# ATSAM3U2E register map
Vendor: Atmel; Series: SAM3U; File version: 0
CPU: CM3 r2p0, selectable endian, MPU, no FPU, 4 interrupt priority bits
Registers are 32-bit, read-write, reset 0x0 unless marked. A register's access mark holds for its fields unless they carry their own. Offsets are from the block's base; [hi:lo] are bit positions; {n}, {i} and the like mark numbered series; 'fields as' and 'values as' point back to an identical list.

## USART0 — Universal Synchronous Asynchronous Receiver Transmitter 0
Base 0x40090000; register names take the prefix USART0_
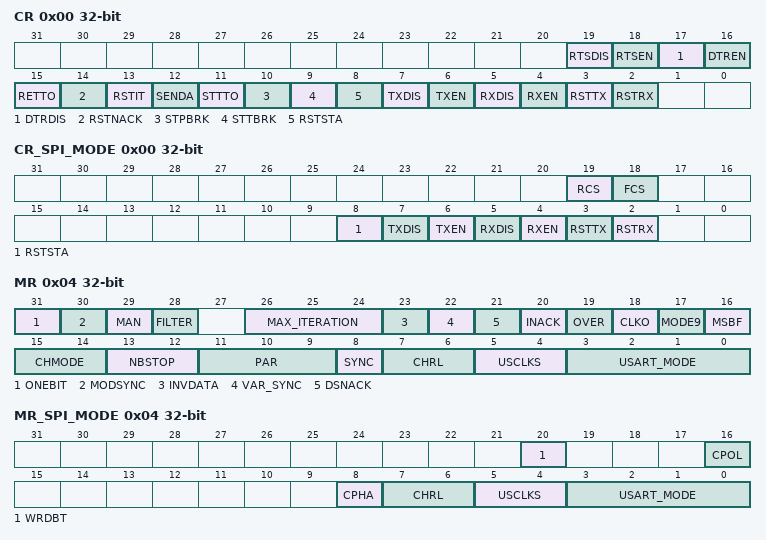
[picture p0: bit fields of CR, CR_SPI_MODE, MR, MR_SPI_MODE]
0x00 CR wo reset not defined — Control Register
  [19] RTSDIS — Request to Send Disable
  [18] RTSEN — Request to Send Enable
  [17] DTRDIS — Data Terminal Ready Disable
  [16] DTREN — Data Terminal Ready Enable
  [15] RETTO — Rearm Time-out
  [14] RSTNACK — Reset Non Acknowledge
  [13] RSTIT — Reset Iterations
  [12] SENDA — Send Address
  [11] STTTO — Start Time-out
  [10] STPBRK — Stop Break
  [9] STTBRK — Start Break
  [8] RSTSTA — Reset Status Bits
  [7] TXDIS — Transmitter Disable
  [6] TXEN — Transmitter Enable
  [5] RXDIS — Receiver Disable
  [4] RXEN — Receiver Enable
  [3] RSTTX — Reset Transmitter
  [2] RSTRX — Reset Receiver
0x00 CR_SPI_MODE wo reset not defined (SPI_MODE view) — Control Register
  [19] RCS — Release SPI Chip Select
  [18] FCS — Force SPI Chip Select
  [8] RSTSTA — Reset Status Bits
  [7] TXDIS — Transmitter Disable
  [6] TXEN — Transmitter Enable
  [5] RXDIS — Receiver Disable
  [4] RXEN — Receiver Enable
  [3] RSTTX — Reset Transmitter
  [2] RSTRX — Reset Receiver
0x04 MR reset not defined — Mode Register
  [31] ONEBIT — Start Frame Delimiter Selector
  [30] MODSYNC — Manchester Synchronization Mode
  [29] MAN — Manchester Encoder/Decoder Enable
  [28] FILTER — Infrared Receive Line Filter
  [26:24] MAX_ITERATION — Maximum Number of Automatic Iteration
  [23] INVDATA — Inverted Data
  [22] VAR_SYNC — Variable Synchronization of Command/Data Sync Start Frame Delimiter
  [21] DSNACK — Disable Successive NACK
  [20] INACK — Inhibit Non Acknowledge
  [19] OVER — Oversampling Mode
  [18] CLKO — Clock Output Select
  [17] MODE9 — 9-bit Character Length
  [16] MSBF — Bit Order
  [15:14] CHMODE — Channel Mode
    0=NORMAL (Normal Mode); 1=AUTOMATIC (Automatic Echo. Receiver input is connected to the TXD pin.); 2=LOCAL_LOOPBACK (Local Loopback. Transmitter output is connected to the Receiver Input.); 3=REMOTE_LOOPBACK (Remote Loopback. RXD pin is internally connected to the TXD pin.)
  [13:12] NBSTOP — Number of Stop Bits
    0=1_BIT (1 stop bit); 1=1_5_BIT (1.5 stop bit (SYNC = 0) or reserved (SYNC = 1)); 2=2_BIT (2 stop bits)
  [11:9] PAR — Parity Type
    0=EVEN (Even parity); 1=ODD (Odd parity); 2=SPACE (Parity forced to 0 (Space)); 3=MARK (Parity forced to 1 (Mark)); 4=NO (No parity); 6=MULTIDROP (Multidrop mode)
  [8] SYNC — Synchronous Mode Select
  [7:6] CHRL — Character Length.
    {v}={v+5}_BIT (Character length is {v+5} bits) (v=0..3)
  [5:4] USCLKS — Clock Selection
    0=MCK (Master Clock MCK is selected); 1=DIV (Internal Clock Divided MCK/DIV (DIV=8) is selected); 3=SCK (Serial Clock SLK is selected)
  [3:0] USART_MODE — USART Mode of Operation
    0=NORMAL (Normal mode); 1=RS485; 2=HW_HANDSHAKING (Hardware Handshaking); 3=MODEM; 4=IS07816_T_0 (IS07816 Protocol: T = 0); 6=IS07816_T_1 (IS07816 Protocol: T = 1); 8=IRDA; 14=SPI_MASTER; 15=SPI_SLAVE
0x04 MR_SPI_MODE reset not defined (SPI_MODE view) — Mode Register
  [20] WRDBT — Wait Read Data Before Transfer
  [16] CPOL — SPI Clock Polarity
  [8] CPHA — SPI Clock Phase
  [7:6] CHRL — Character Length.
    3=8_BIT (Character length is 8 bits)
  [5:4] USCLKS — Clock Selection
    values as MR.USCLKS
  [3:0] USART_MODE — USART Mode of Operation
    14=SPI_MASTER; 15=SPI_SLAVE
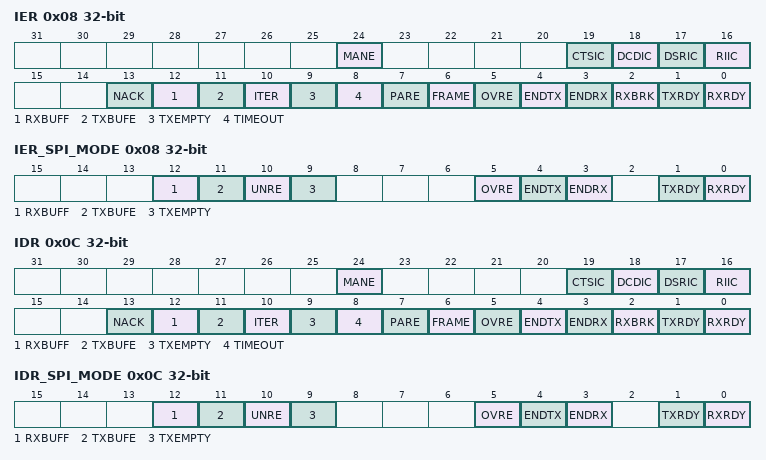
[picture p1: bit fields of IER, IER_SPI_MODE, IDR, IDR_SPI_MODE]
0x08 IER wo reset not defined — Interrupt Enable Register
  [24] MANE — Manchester Error Interrupt Enable
  [19] CTSIC — Clear to Send Input Change Interrupt Enable
  [18] DCDIC — Data Carrier Detect Input Change Interrupt Enable
  [17] DSRIC — Data Set Ready Input Change Enable
  [16] RIIC — Ring Indicator Input Change Enable
  [13] NACK — Non AcknowledgeInterrupt Enable
  [12] RXBUFF — Buffer Full Interrupt Enable (available in all USART modes of operation)
  [11] TXBUFE — Buffer Empty Interrupt Enable (available in all USART modes of operation)
  [10] ITER — Max number of Repetitions Reached Interrupt Enable
  [9] TXEMPTY — TXEMPTY Interrupt Enable
  [8] TIMEOUT — Time-out Interrupt Enable
  [7] PARE — Parity Error Interrupt Enable
  [6] FRAME — Framing Error Interrupt Enable
  [5] OVRE — Overrun Error Interrupt Enable
  [4] ENDTX — End of Transmit Interrupt Enable (available in all USART modes of operation)
  [3] ENDRX — End of Receive Transfer Interrupt Enable (available in all USART modes of operation)
  [2] RXBRK — Receiver Break Interrupt Enable
  [1] TXRDY — TXRDY Interrupt Enable
  [0] RXRDY — RXRDY Interrupt Enable
0x08 IER_SPI_MODE wo reset not defined (SPI_MODE view) — Interrupt Enable Register
  [12] RXBUFF
  [11] TXBUFE
  [10] UNRE — SPI Underrun Error Interrupt Enable
  [9] TXEMPTY — TXEMPTY Interrupt Enable
  [5] OVRE — Overrun Error Interrupt Enable
  [4] ENDTX
  [3] ENDRX
  [1] TXRDY — TXRDY Interrupt Enable
  [0] RXRDY — RXRDY Interrupt Enable
0x0C IDR wo reset not defined — Interrupt Disable Register
  [24] MANE — Manchester Error Interrupt Disable
  [19] CTSIC — Clear to Send Input Change Interrupt Disable
  [18] DCDIC — Data Carrier Detect Input Change Interrupt Disable
  [17] DSRIC — Data Set Ready Input Change Disable
  [16] RIIC — Ring Indicator Input Change Disable
  [13] NACK — Non AcknowledgeInterrupt Disable
  [12] RXBUFF — Buffer Full Interrupt Disable (available in all USART modes of operation)
  [11] TXBUFE — Buffer Empty Interrupt Disable (available in all USART modes of operation)
  [10] ITER — Max Number of Repetitions Reached Interrupt Disable
  [9] TXEMPTY — TXEMPTY Interrupt Disable
  [8] TIMEOUT — Time-out Interrupt Disable
  [7] PARE — Parity Error Interrupt Disable
  [6] FRAME — Framing Error Interrupt Disable
  [5] OVRE — Overrun Error Interrupt Enable
  [4] ENDTX — End of Transmit Interrupt Disable (available in all USART modes of operation)
  [3] ENDRX — End of Receive Transfer Interrupt Disable (available in all USART modes of operation)
  [2] RXBRK — Receiver Break Interrupt Disable
  [1] TXRDY — TXRDY Interrupt Disable
  [0] RXRDY — RXRDY Interrupt Disable
0x0C IDR_SPI_MODE wo reset not defined (SPI_MODE view) — Interrupt Disable Register
  [12] RXBUFF
  [11] TXBUFE
  [10] UNRE — SPI Underrun Error Interrupt Disable
  [9] TXEMPTY — TXEMPTY Interrupt Disable
  [5] OVRE — Overrun Error Interrupt Disable
  [4] ENDTX
  [3] ENDRX
  [1] TXRDY — TXRDY Interrupt Disable
  [0] RXRDY — RXRDY Interrupt Disable
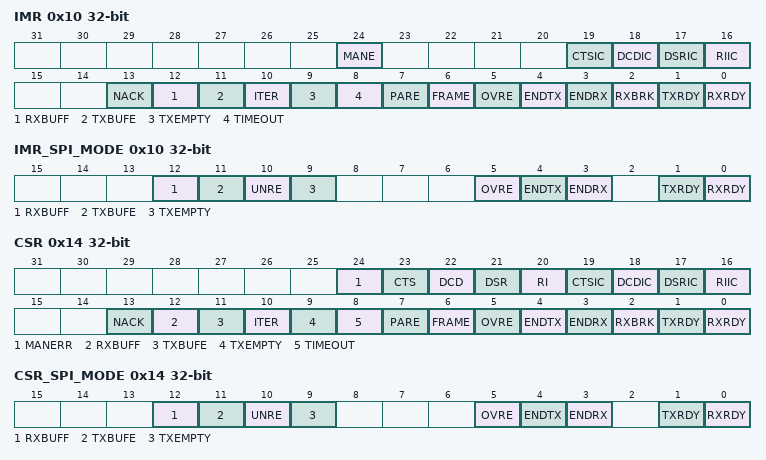
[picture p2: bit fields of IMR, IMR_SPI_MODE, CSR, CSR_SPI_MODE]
0x10 IMR ro — Interrupt Mask Register
  [24] MANE — Manchester Error Interrupt Mask
  [19] CTSIC — Clear to Send Input Change Interrupt Mask
  [18] DCDIC — Data Carrier Detect Input Change Interrupt Mask
  [17] DSRIC — Data Set Ready Input Change Mask
  [16] RIIC — Ring Indicator Input Change Mask
  [13] NACK — Non AcknowledgeInterrupt Mask
  [12] RXBUFF — Buffer Full Interrupt Mask (available in all USART modes of operation)
  [11] TXBUFE — Buffer Empty Interrupt Mask (available in all USART modes of operation)
  [10] ITER — Max Number of Repetitions Reached Interrupt Mask
  [9] TXEMPTY — TXEMPTY Interrupt Mask
  [8] TIMEOUT — Time-out Interrupt Mask
  [7] PARE — Parity Error Interrupt Mask
  [6] FRAME — Framing Error Interrupt Mask
  [5] OVRE — Overrun Error Interrupt Mask
  [4] ENDTX — End of Transmit Interrupt Mask (available in all USART modes of operation)
  [3] ENDRX — End of Receive Transfer Interrupt Mask (available in all USART modes of operation)
  [2] RXBRK — Receiver Break Interrupt Mask
  [1] TXRDY — TXRDY Interrupt Mask
  [0] RXRDY — RXRDY Interrupt Mask
0x10 IMR_SPI_MODE ro (SPI_MODE view) — Interrupt Mask Register
  [12] RXBUFF
  [11] TXBUFE
  [10] UNRE — SPI Underrun Error Interrupt Mask
  [9] TXEMPTY — TXEMPTY Interrupt Mask
  [5] OVRE — Overrun Error Interrupt Mask
  [4] ENDTX
  [3] ENDRX
  [1] TXRDY — TXRDY Interrupt Mask
  [0] RXRDY — RXRDY Interrupt Mask
0x14 CSR ro reset not defined — Channel Status Register
  [24] MANERR — Manchester Error
  [23] CTS — Image of CTS Input
  [22] DCD — Image of DCD Input
  [21] DSR — Image of DSR Input
  [20] RI — Image of RI Input
  [19] CTSIC — Clear to Send Input Change Flag
  [18] DCDIC — Data Carrier Detect Input Change Flag
  [17] DSRIC — Data Set Ready Input Change Flag
  [16] RIIC — Ring Indicator Input Change Flag
  [13] NACK — Non AcknowledgeInterrupt
  [12] RXBUFF — Reception Buffer Full
  [11] TXBUFE — Transmission Buffer Empty
  [10] ITER — Max Number of Repetitions Reached
  [9] TXEMPTY — Transmitter Empty
  [8] TIMEOUT — Receiver Time-out
  [7] PARE — Parity Error
  [6] FRAME — Framing Error
  [5] OVRE — Overrun Error
  [4] ENDTX — End of Transmitter Transfer
  [3] ENDRX — End of Receiver Transfer
  [2] RXBRK — Break Received/End of Break
  [1] TXRDY — Transmitter Ready
  [0] RXRDY — Receiver Ready
0x14 CSR_SPI_MODE ro reset not defined (SPI_MODE view) — Channel Status Register
  [12] RXBUFF
  [11] TXBUFE
  [10] UNRE — Underrun Error
  [9] TXEMPTY — Transmitter Empty
  [5] OVRE — Overrun Error
  [4] ENDTX
  [3] ENDRX
  [1] TXRDY — Transmitter Ready
  [0] RXRDY — Receiver Ready
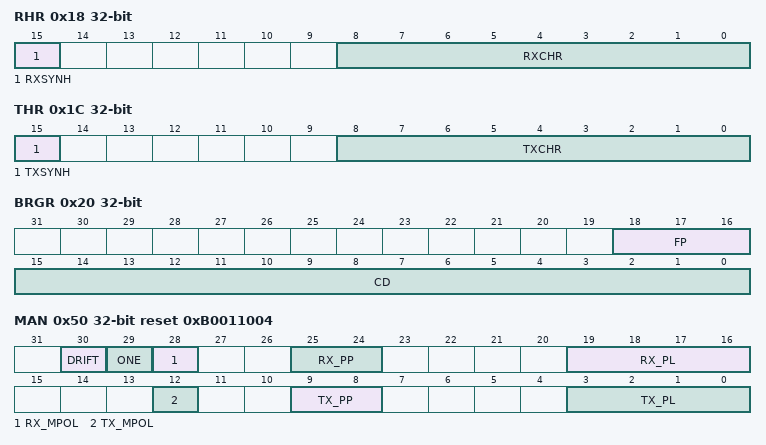
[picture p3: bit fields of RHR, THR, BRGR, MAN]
0x18 RHR ro — Receiver Holding Register
  [15] RXSYNH — Received Sync
  [8:0] RXCHR — Received Character
0x1C THR wo reset not defined — Transmitter Holding Register
  [15] TXSYNH — Sync Field to be Transmitted
  [8:0] TXCHR — Character to be Transmitted
0x20 BRGR — Baud Rate Generator Register
  [18:16] FP — Fractional Part
  [15:0] CD — Clock Divider
0x24 RTOR — Receiver Time-out Register
  [15:0] TO — Time-out Value
0x28 TTGR — Transmitter Timeguard Register
  [7:0] TG — Timeguard Value
0x40 FIDI reset 0x174 — FI DI Ratio Register
  [15:0] FI_DI_RATIO — FI Over DI Ratio Value
0x44 NER ro reset not defined — Number of Errors Register
  [7:0] NB_ERRORS — Number of Errors
0x4C IF — IrDA Filter Register
  [7:0] IRDA_FILTER
0x50 MAN reset 0xB0011004 — Manchester Encoder Decoder Register
  [30] DRIFT — Drift Compensation
  [29] ONE — Must Be Set to 1
  [28] RX_MPOL — Receiver Manchester Polarity
  [25:24] RX_PP — Receiver Preamble Pattern detected
    0=ALL_ONE (The preamble is composed of '1's); 1=ALL_ZERO (The preamble is composed of '0's); 2=ZERO_ONE (The preamble is composed of '01's); 3=ONE_ZERO (The preamble is composed of '10's)
  [19:16] RX_PL — Receiver Preamble Length
  [12] TX_MPOL — Transmitter Manchester Polarity
  [9:8] TX_PP — Transmitter Preamble Pattern
    values as RX_PP
  [3:0] TX_PL — Transmitter Preamble Length
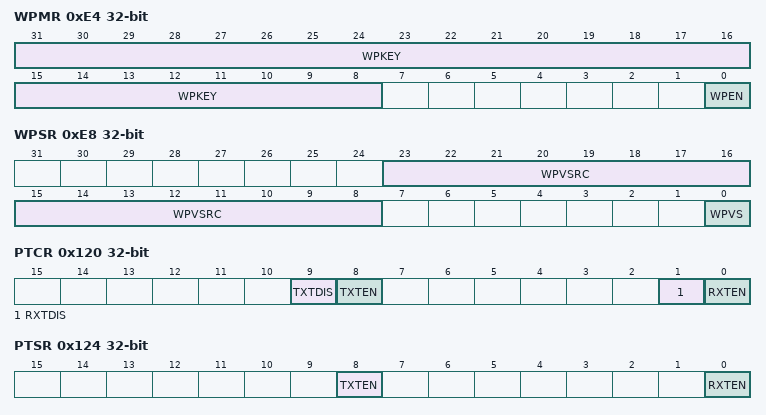
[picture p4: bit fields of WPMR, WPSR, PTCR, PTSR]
0xE4 WPMR — Write Protect Mode Register
  [31:8] WPKEY — Write Protect KEY.
    0x555341=PASSWD (Writing any other value in this field aborts the write operation of the WPEN bit. Always reads as 0.)
  [0] WPEN — Write Protect Enable
0xE8 WPSR ro — Write Protect Status Register
  [23:8] WPVSRC — Write Protect Violation Source
  [0] WPVS — Write Protect Violation Status
0x100 RPR — Receive Pointer Register
  [31:0] RXPTR
0x104 RCR — Receive Counter Register
  [15:0] RXCTR
0x108 TPR — Transmit Pointer Register
  [31:0] TXPTR — Transmit Counter Register
0x10C TCR — Transmit Counter Register
  [15:0] TXCTR
0x110 RNPR — Receive Next Pointer Register
  [31:0] RXNPTR — Receive Next Pointer
0x114 RNCR — Receive Next Counter Register
  [15:0] RXNCTR — Receive Next Counter
0x118 TNPR — Transmit Next Pointer Register
  [31:0] TXNPTR — Transmit Next Pointer
0x11C TNCR — Transmit Next Counter Register
  [15:0] TXNCTR — Transmit Counter Next
0x120 PTCR wo — Transfer Control Register
  [9] TXTDIS — Transmitter Transfer Disable
  [8] TXTEN — Transmitter Transfer Enable
  [1] RXTDIS — Receiver Transfer Disable
  [0] RXTEN — Receiver Transfer Enable
0x124 PTSR ro — Transfer Status Register
  [8] TXTEN — Transmitter Transfer Enable
  [0] RXTEN — Receiver Transfer Enable

## USART1 — Universal Synchronous Asynchronous Receiver Transmitter 1
Base 0x40094000; register names take the prefix USART1_
Registers as USART0.

## USART2 — Universal Synchronous Asynchronous Receiver Transmitter 2
Base 0x40098000; register names take the prefix USART2_
Registers as USART0.

## USART3 — Universal Synchronous Asynchronous Receiver Transmitter 3
Base 0x4009C000; register names take the prefix USART3_
Registers as USART0.

## Notices in the file
SAM Software Package License
Copyright (c) 2015, Atmel Corporation
All rights reserved.
Redistribution and use in source and binary forms, with or without
modification, are permitted provided that the following condition is met:
- Redistributions of source code must retain the above copyright notice,
this list of conditions and the disclaimer below.
Atmel's name may not be used to endorse or promote products derived from
this software without specific prior written permission.
DISCLAIMER:  THIS SOFTWARE IS PROVIDED BY ATMEL "AS IS" AND ANY EXPRESS OR
IMPLIED WARRANTIES, INCLUDING, BUT NOT LIMITED TO, THE IMPLIED WARRANTIES OF
MERCHANTABILITY, FITNESS FOR A PARTICULAR PURPOSE AND NON-INFRINGEMENT ARE
DISCLAIMED. IN NO EVENT SHALL ATMEL BE LIABLE FOR ANY DIRECT, INDIRECT,
INCIDENTAL, SPECIAL, EXEMPLARY, OR CONSEQUENTIAL DAMAGES (INCLUDING, BUT NOT
LIMITED TO, PROCUREMENT OF SUBSTITUTE GOODS OR SERVICES; LOSS OF USE, DATA,
OR PROFITS; OR BUSINESS INTERRUPTION) HOWEVER CAUSED AND ON ANY THEORY OF
LIABILITY, WHETHER IN CONTRACT, STRICT LIABILITY, OR TORT (INCLUDING
NEGLIGENCE OR OTHERWISE) ARISING IN ANY WAY OUT OF THE USE OF THIS SOFTWARE,
EVEN IF ADVISED OF THE POSSIBILITY OF SUCH DAMAGE.
